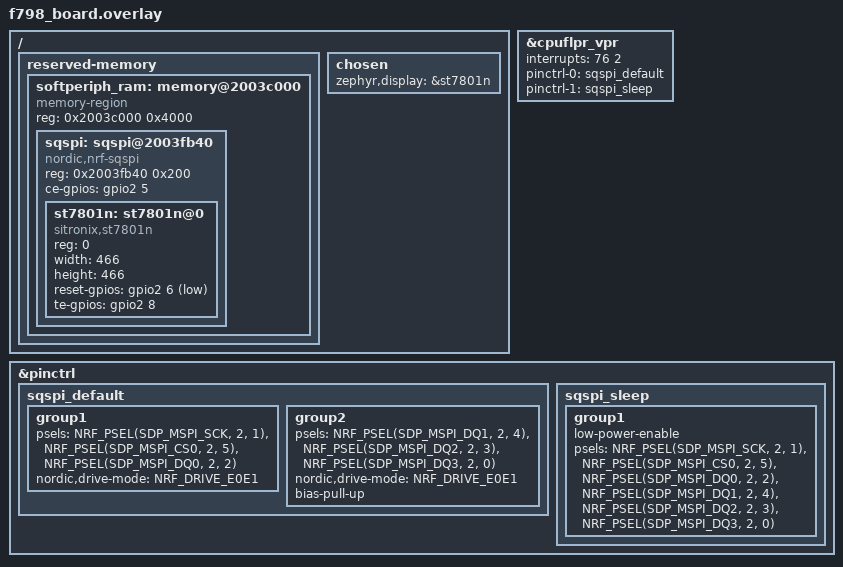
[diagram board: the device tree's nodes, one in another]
#include <dt-bindings/gpio/gpio.h>
#include <dt-bindings/pinctrl/nrf-pinctrl.h>

&cpuflpr_vpr {
    status = "okay";
    interrupts = <76 2>;
    pinctrl-0 = <&sqspi_default>;
    pinctrl-1 = <&sqspi_sleep>;
    pinctrl-names = "default", "sleep";
    /delete-property/ execution-memory;
};

/ {
    reserved-memory {
        #address-cells = <1>;
        #size-cells = <1>;
        ranges;

        softperiph_ram: memory@2003c000 {
            compatible = "memory-region";
            reg = <0x2003c000 0x4000>;
            #address-cells = <1>;
            #size-cells = <1>;

            sqspi: sqspi@2003fb40 {
                compatible = "nordic,nrf-sqspi";
                reg = <0x2003fb40 0x200>;   /* ← 绝对地址 */
                status = "okay";
                #address-cells = <1>;
                #size-cells = <0>;
                ce-gpios = <&gpio2 5 GPIO_ACTIVE_HIGH>;

                st7801n: st7801n@0 {
                    compatible = "sitronix,st7801n";
                    reg = <0>;
                    width = <466>;
                    height = <466>;
                    reset-gpios = <&gpio2 6 GPIO_ACTIVE_LOW>;
                    te-gpios    = <&gpio2 8 GPIO_ACTIVE_HIGH>;
                    status = "okay";
                };
            };
        };
    };

    chosen {
        zephyr,display = &st7801n;
    };
};

&pinctrl {
    sqspi_default: sqspi_default {
        group1 {
            psels = <NRF_PSEL(SDP_MSPI_SCK, 2, 1)>,
                    <NRF_PSEL(SDP_MSPI_CS0, 2, 5)>,
                    <NRF_PSEL(SDP_MSPI_DQ0, 2, 2)>;
            nordic,drive-mode = <NRF_DRIVE_E0E1>;
        };
        group2 {
            psels = <NRF_PSEL(SDP_MSPI_DQ1, 2, 4)>,
                    <NRF_PSEL(SDP_MSPI_DQ2, 2, 3)>,
                    <NRF_PSEL(SDP_MSPI_DQ3, 2, 0)>;
            nordic,drive-mode = <NRF_DRIVE_E0E1>;
            bias-pull-up;
        };
    };

    sqspi_sleep: sqspi_sleep {
        group1 {
            low-power-enable;
            psels = <NRF_PSEL(SDP_MSPI_SCK, 2, 1)>,
                    <NRF_PSEL(SDP_MSPI_CS0, 2, 5)>,
                    <NRF_PSEL(SDP_MSPI_DQ0, 2, 2)>,
                    <NRF_PSEL(SDP_MSPI_DQ1, 2, 4)>,
                    <NRF_PSEL(SDP_MSPI_DQ2, 2, 3)>,
                    <NRF_PSEL(SDP_MSPI_DQ3, 2, 0)>;
        };
    };
};
